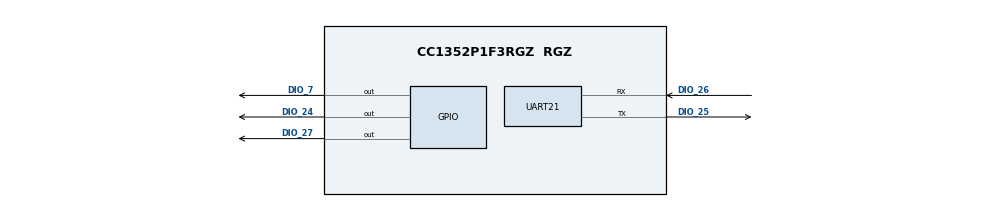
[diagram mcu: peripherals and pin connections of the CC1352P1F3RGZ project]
/**
 * @cliArgs --device "CC1352P1F3RGZ" --package "RGZ" --part "Default" --rtos "nortos" --product "simplelink_cc13xx_cc26xx_sdk@7.40.00.77"
 * @versions {"tool":"1.18.1+3343"}
 */
scripting.excludeFromBuild("ti_utils_build_linker.cmd.genlibs");

/**
 * Import the modules used in this configuration.
 */
const CCFG     = scripting.addModule("/ti/devices/CCFG");
const custom   = scripting.addModule("/ti/devices/radioconfig/custom");
const rfdesign = scripting.addModule("/ti/devices/radioconfig/rfdesign");
const Board    = scripting.addModule("/ti/drivers/Board");
const GPIO     = scripting.addModule("/ti/drivers/GPIO");
const GPIO1    = GPIO.addInstance();
const GPIO2    = GPIO.addInstance();
const GPIO3    = GPIO.addInstance();
const Power    = scripting.addModule("/ti/drivers/Power");
const RF       = scripting.addModule("/ti/drivers/RF");
const Timer    = scripting.addModule("/ti/drivers/Timer", {}, false);
const Timer1   = Timer.addInstance();
const UART2    = scripting.addModule("/ti/drivers/UART2", {}, false);
const UART21   = UART2.addInstance();

/**
 * Write custom configuration values to the imported modules.
 */
CCFG.AonTap             = true;
CCFG.TestTap            = true;
CCFG.Pbist2Tap          = true;
CCFG.Pbist1Tap          = true;
CCFG.FailureAnalysis    = true;
CCFG.enableDCDC         = false;
CCFG.ccfgTemplate.$name = "ti_devices_CCFG_CCFGCC26XXTemplate0";

custom.ble                                                        = ["bt5le1mp10"];
custom.prop4                                                      = ["custom433"];
custom.radioConfigbt5le1mp10.$name                                = "ti_devices_radioconfig_settings_ble0";
custom.radioConfigbt5le1mp10.codeExportConfig.$name               = "ti_devices_radioconfig_code_export_param0";
custom.radioConfigbt5le1mp10.codeExportConfig.symGenMethod        = "Custom";
custom.radioConfigbt5le1mp10.codeExportConfig.cmdFs               = "RF_ble_cmdFs";
custom.radioConfigbt5le1mp10.codeExportConfig.cmdBle5RadioSetupPa = "RF_ble_cmdBle5RadioSetup";
custom.radioConfigbt5le1mp10.codeExportConfig.cmdBle5AdvAux       = "RF_ble_cmdBle5AdvAux";
custom.radioConfigbt5le1mp10.codeExportConfig.cmdBle5GenericRx    = "RF_ble_cmdBle5GenericRx";
custom.radioConfigbt5le1mp10.codeExportConfig.rfMode              = "RF_ble_mode";
custom.radioConfigbt5le1mp10.codeExportConfig.txPower             = "RF_ble_txPowerTable";
custom.radioConfigbt5le1mp10.codeExportConfig.overrides           = "RF_ble_overrides";
custom.radioConfigbt5le1mp10.codeExportConfig.txPowerSize         = "RF_BLE_TX_POWER_TABLE_SIZE";
custom.radioConfigbt5le1mp10.codeExportConfig.useMulti            = true;
custom.radioConfigcustom433.$name                                 = "ti_devices_radioconfig_settings_prop0";
custom.radioConfigcustom433.txPower433                            = "12.5";
custom.radioConfigcustom433.codeExportConfig.$name                = "ti_devices_radioconfig_code_export_param1";
custom.radioConfigcustom433.codeExportConfig.cpePatch             = "rf_patch_cpe_prop_psip";

rfdesign.rfDesign = "LAUNCHXL-CC1352P-4";
rfdesign.pa20     = "fbSub1g";

GPIO1.mode            = "Output";
GPIO1.$name           = "CONFIG_GPIO_LED_0";
GPIO1.gpioPin.$assign = "DIO_7";

GPIO2.$name           = "CONFIG_GPIO_0";
GPIO2.mode            = "Output";
GPIO2.gpioPin.$assign = "DIO_27";

GPIO3.$name           = "CONFIG_GPIO_1";
GPIO3.mode            = "Output";
GPIO3.gpioPin.$assign = "DIO_24";

Power.enablePolicy = false;

RF.globalCallbackFunction                   = "rfDriverCallback";
RF.pinSelectionAntenna                      = 2;
RF.rfAntennaPinSymbol0                      = "CONFIG_GPIO_ENABLE_RX";
RF.rfAntennaPinSymbol1                      = "CONFIG_GPIO_ENABLE_TX";
RF.rfAntennaPin0.$assign                    = "DIO_5";
RF.rfAntennaPin1.$assign                    = "DIO_6";
RF.rfAntennaPin0Instance.initialOutputState = scripting.forceWrite("Low");
RF.rfAntennaPin0Instance.invert             = true;
RF.rfAntennaPin1Instance.initialOutputState = scripting.forceWrite("Low");
RF.rfAntennaPin1Instance.invert             = true;

Timer1.$name               = "CONFIG_TIMER_0";
Timer1.timerType           = "32 Bits";
Timer1.timerInstance.$name = "CONFIG_GPTIMER_0";

UART21.$name              = "CONFIG_UART2_0";
UART21.uart.$assign       = "UART0";
UART21.uart.txPin.$assign = "DIO_25";
UART21.uart.rxPin.$assign = "DIO_26";

/**
 * These are the reserved peripherals and settings in this configuration
 */
const iJTAG1        = scripting.addPeripheral("JTAG");
iJTAG1.$name        = "JTAG";
iJTAG1.$assign      = "JTAG";
iJTAG1.TMSC.$assign = "JTAG_TMSC";
iJTAG1.TCKC.$assign = "JTAG_TCKC";

/**
 * Pinmux solution for unlocked pins/peripherals. This ensures that minor changes to the automatic solver in a future
 * version of the tool will not impact the pinmux you originally saw.  These lines can be completely deleted in order to
 * re-solve from scratch.
 */
Timer1.timerInstance.timer.$suggestSolution = "GPTM0";
